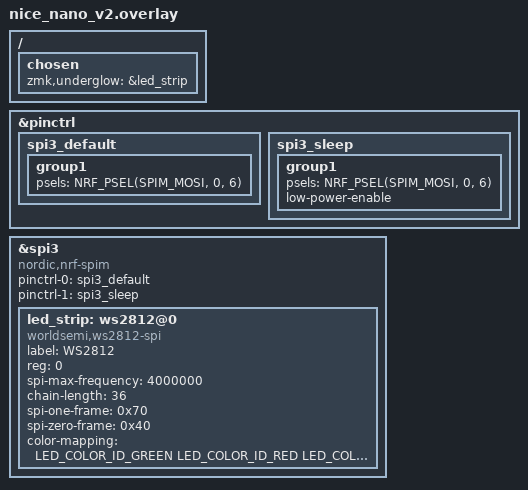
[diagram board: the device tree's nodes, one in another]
#include <dt-bindings/led/led.h>

/* Sofle RGB (MX) — WS2812 data on P0.06, 36 LEDs per half
 * (underglow underneath + per-key). Different pin/count from the Choc
 * variant (P0.08 / 30). */
&pinctrl {
    spi3_default: spi3_default {
        group1 {
            psels = <NRF_PSEL(SPIM_MOSI, 0, 6)>;
        };
    };
    spi3_sleep: spi3_sleep {
        group1 {
            psels = <NRF_PSEL(SPIM_MOSI, 0, 6)>;
            low-power-enable;
        };
    };
};

&spi3 {
    compatible = "nordic,nrf-spim";
    status = "okay";
    pinctrl-0 = <&spi3_default>;
    pinctrl-1 = <&spi3_sleep>;
    pinctrl-names = "default", "sleep";

    led_strip: ws2812@0 {
        compatible = "worldsemi,ws2812-spi";
        label = "WS2812";

        reg = <0>; /* ignored, but necessary for SPI bindings */
        spi-max-frequency = <4000000>;

        chain-length = <36>; /* 36 per half: per-key + underglow */
        spi-one-frame = <0x70>;
        spi-zero-frame = <0x40>;

        color-mapping = <LED_COLOR_ID_GREEN LED_COLOR_ID_RED LED_COLOR_ID_BLUE>;
    };
};

/ {
    chosen {
        zmk,underglow = &led_strip;
    };
};
